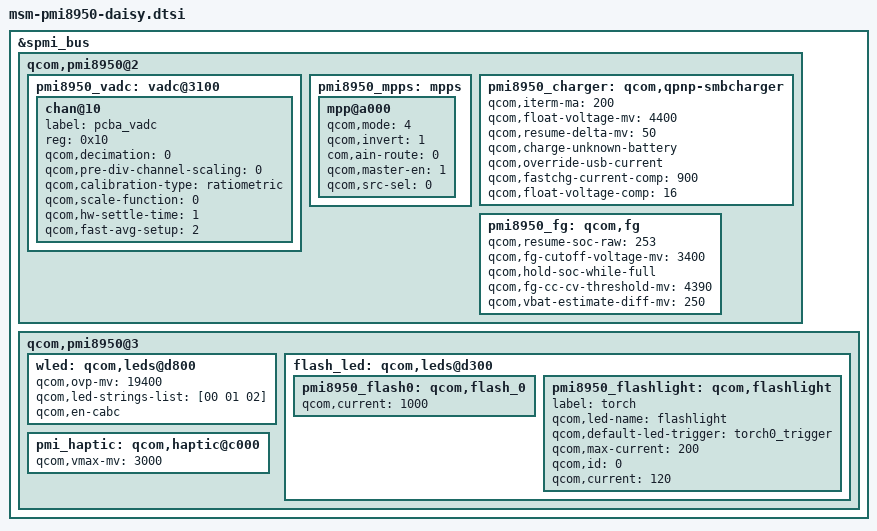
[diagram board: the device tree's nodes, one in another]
/* Copyright (c) 2015-2017, The Linux Foundation. All rights reserved.
 * Copyright (C) 2018 XiaoMi, Inc.
 *
 * This program is free software; you can redistribute it and/or modify
 * it under the terms of the GNU General Public License version 2 and
 * only version 2 as published by the Free Software Foundation.
 *
 * This program is distributed in the hope that it will be useful,
 * but WITHOUT ANY WARRANTY; without even the implied warranty of
 * MERCHANTABILITY or FITNESS FOR A PARTICULAR PURPOSE.  See the
 * GNU General Public License for more details.
 */

#include <dt-bindings/msm/power-on.h>

&spmi_bus {

	qcom,pmi8950@2 {

		pmi8950_vadc: vadc@3100 {
			chan@10 {
				label = "pcba_vadc";
				reg = <0x10>;
				qcom,decimation = <0>;
				qcom,pre-div-channel-scaling = <0>; //1:1
				qcom,calibration-type = "ratiometric";
				qcom,scale-function = <0>;
				qcom,hw-settle-time = <1>;
				qcom,fast-avg-setup = <2>;
			};
		};

		pmi8950_mpps: mpps {
			mpp@a000 {
				qcom,mode = <4>; /* AIN input */
				qcom,invert = <1>; /* Enable MPP */
				com,ain-route = <0>; /* AMUX 5 */
				qcom,master-en = <1>;
				qcom,src-sel = <0>; /* Function constant */
				status = "okay";
			};
		};

		pmi8950_charger: qcom,qpnp-smbcharger {

			qcom,iterm-ma = <200>;
			qcom,float-voltage-mv = <4400>;
			qcom,resume-delta-mv = <50>;

			qcom,charge-unknown-battery;
			
			/delete-property/ qcom,parallel-usb-min-current-ma;
			/delete-property/ qcom,parallel-usb-9v-min-current-ma;
			/delete-property/ qcom,parallel-allowed-lowering-ma;
			
			qcom,override-usb-current;
			qcom,fastchg-current-comp = <900>;
			qcom,float-voltage-comp = <16>;
		};

		pmi8950_fg: qcom,fg {
			/delete-property/ qcom,resume-soc;
			qcom,resume-soc-raw = <253>;

			qcom,fg-cutoff-voltage-mv = <3400>;

			qcom,hold-soc-while-full;

			qcom,fg-cc-cv-threshold-mv =<4390>;
			qcom,vbat-estimate-diff-mv = <250>;
			};
		};

	qcom,pmi8950@3 {

		wled: qcom,leds@d800 {
			qcom,ovp-mv = <19400>;
			qcom,led-strings-list = [00 01 02];
			qcom,en-cabc;
		};

		flash_led: qcom,leds@d300 {
			pmi8950_flash0: qcom,flash_0 {
				qcom,current = <1000>;
			};

			pmi8950_flashlight: qcom,flashlight {
				label = "torch";
				qcom,led-name = "flashlight";
				qcom,default-led-trigger =
				                "torch0_trigger";
				qcom,max-current = <200>;
				qcom,id = <0>;
				qcom,current = <120>;
				};
			};

		pmi_haptic: qcom,haptic@c000 {
			qcom,vmax-mv = <3000>;
		};
	};
};
